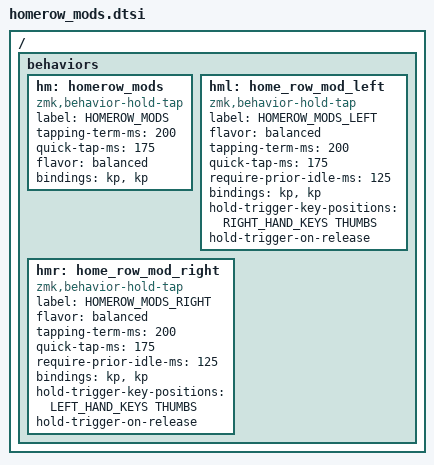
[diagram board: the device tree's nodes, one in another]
#include "adv360_key_positions.h"

/ {
    behaviors {
        hm: homerow_mods {
            compatible = "zmk,behavior-hold-tap";
            label = "HOMEROW_MODS";
            #binding-cells = <2>;

            tapping-term-ms = <200>;
            quick-tap-ms = <175>;
            flavor = "balanced";

            bindings = <&kp>, <&kp>;
        };

        hml: home_row_mod_left {
            compatible = "zmk,behavior-hold-tap";
            label = "HOMEROW_MODS_LEFT";
            #binding-cells = <2>;

            flavor = "balanced";
            tapping-term-ms = <200>;
            quick-tap-ms = <175>;
            require-prior-idle-ms = <125>;

            bindings = <&kp>, <&kp>;

            hold-trigger-key-positions = <RIGHT_HAND_KEYS THUMBS>;
            hold-trigger-on-release;
        };

        hmr: home_row_mod_right {
            compatible = "zmk,behavior-hold-tap";
            label = "HOMEROW_MODS_RIGHT";
            #binding-cells = <2>;

            flavor = "balanced";
            tapping-term-ms = <200>;
            quick-tap-ms = <175>;
            require-prior-idle-ms = <125>;

            bindings = <&kp>, <&kp>;

            hold-trigger-key-positions = <LEFT_HAND_KEYS THUMBS>;
            hold-trigger-on-release;
        };
    };
};
